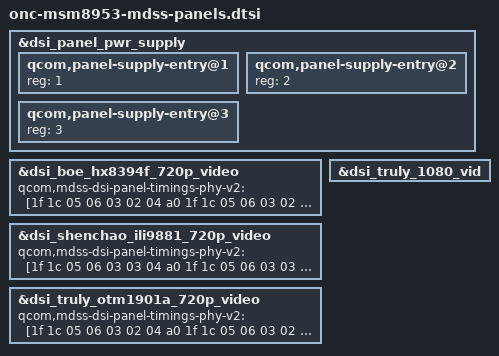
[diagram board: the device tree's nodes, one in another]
/*
 * Copyright (c) 2015-2019, The Linux Foundation. All rights reserved.
 * Copyright (C) 2020-2024 XiaoMi, Inc.
 *
 * This program is free software; you can redistribute it and/or modify
 * it under the terms of the GNU General Public License version 2 and
 * only version 2 as published by the Free Software Foundation.
 */

/* Include the purely added panel definition files */
#include "display/dsi-panel-boe-hx8394f-720p-video.dtsi"
#include "display/dsi-panel-shenchao-ili9881-720p-video.dtsi"
#include "display/dsi-panel-truly-otm1901a-720p-video.dtsi"

&dsi_panel_pwr_supply {
	/delete-node/ qcom,panel-supply-entry@0;
	qcom,panel-supply-entry@1 {
		reg = <1>;
	};
	qcom,panel-supply-entry@2 {
		reg = <2>;
	};
	qcom,panel-supply-entry@3 {
		reg = <3>;
	};
};

&dsi_boe_hx8394f_720p_video {
	qcom,mdss-dsi-panel-timings-phy-v2 = [1f 1c 05 06 03 02 04 a0
		1f 1c 05 06 03 02 04 a0
		1f 1c 05 06 03 02 04 a0
		1f 1c 05 06 03 02 04 a0
		1f 11 05 06 03 02 04 a0];
};

&dsi_shenchao_ili9881_720p_video {
	qcom,mdss-dsi-panel-timings-phy-v2 = [1f 1c 05 06 03 03 04 a0
		1f 1c 05 06 03 03 04 a0
		1f 1c 05 06 03 03 04 a0
		1f 1c 05 06 03 03 04 a0
		1f 10 05 06 03 03 04 a0];
};

&dsi_truly_otm1901a_720p_video {
	qcom,mdss-dsi-panel-timings-phy-v2 = [1f 1c 05 06 03 02 04 a0
		1f 1c 05 06 03 02 04 a0
		1f 1c 05 06 03 02 04 a0
		1f 1c 05 06 03 02 04 a0
		1f 11 05 06 03 02 04 a0];
};

&dsi_truly_1080_vid {
	/delete-property/ qcom,esd-check-enabled;
};
